# nrf52 register map
Vendor: Nordic Semiconductor; Series: nrf52; File version: 1
CPU: CM4 r0p1, little endian, MPU, FPU, 3 interrupt priority bits
Registers are 32-bit, read-write, reset 0x0 unless marked. A register's access mark holds for its fields unless they carry their own. Offsets are from the block's base; [hi:lo] are bit positions; lines under a group give offsets from that group; {n}, {i} and the like mark numbered series.

## FICR — Factory Information Configuration Registers
Base 0x10000000
0x10 CODEPAGESIZE ro reset 0xFFFFFFFF — Code memory page size
0x14 CODESIZE ro reset 0xFFFFFFFF — Code memory size
  [31:0] CODESIZE — Code memory size in number of pages
{0x60+4i} DEVICEID[{i}] (i=0..1) ro reset 0xFFFFFFFF — Description collection: Device identifier
  [31:0] DEVICEID — 64 bit unique device identifier
{0x80+4i} ER[{i}] (i=0..3) ro reset 0xFFFFFFFF — Description collection: Encryption Root, word n
  [31:0] ER — Encryption Root, word n
{0x90+4i} IR[{i}] (i=0..3) ro reset 0xFFFFFFFF — Description collection: Identity Root, word n
  [31:0] IR — Identity Root, word n
0xA0 DEVICEADDRTYPE ro reset 0xFFFFFFFF — Device address type
  [0] DEVICEADDRTYPE
    0=Public address; 1=Random address
{0xA4+4i} DEVICEADDR[{i}] (i=0..1) ro reset 0xFFFFFFFF — Description collection: Device address n
  [31:0] DEVICEADDR — 48 bit device address
0x100 INFO group — Device info
  0x00 PART ro reset 0x52832 — Part code
    [31:0] PART
      0x52832=N52832 (nRF52832); 0xFFFFFFFF=Unspecified
  0x04 VARIANT ro reset 0x41414142 — Part Variant, Hardware version and Production configuration
    [31:0] VARIANT — Part Variant, Hardware version and Production configuration, encoded as ASCII
      0x41414141=AAAA; 0x41414143=AAAC; 0x41414241=AABA; 0x41414242=AABB; 0x41414230=AAB0; 0x41424230=ABB0; 0x41414530=AAE0; 0x41424530=ABE0; 0x41414742=AAGB; 0x41424742=ABGB; 0x41414730=AAG0; 0x41424730=ABG0; 0xFFFFFFFF=Unspecified
  0x08 PACKAGE ro reset 0x2000 — Package option
    [31:0] PACKAGE
      0x2000=QF (QFxx - 48-pin QFN); 0x2001=CH (CHxx - 7x8 WLCSP 56 balls); 0x2002=CI (CIxx - 7x8 WLCSP 56 balls); 0x2005=CK (CKxx - 7x8 WLCSP 56 balls with backside coating for light protection); 0xFFFFFFFF=Unspecified
  0x0C RAM ro reset 0x40 — RAM variant
    [31:0] RAM
      16=K16 (16 kByte RAM); 32=K32 (32 kByte RAM); 64=K64 (64 kByte RAM); 0xFFFFFFFF=Unspecified
  0x10 FLASH ro reset 0x200 — Flash variant
    [31:0] FLASH
      128=K128 (128 kByte FLASH); 0x100=K256 (256 kByte FLASH); 0x200=K512 (512 kByte FLASH); 0xFFFFFFFF=Unspecified
0x404 TEMP group — Registers storing factory TEMP module linearization coefficients
  0x00 A0 ro reset 0x320 — Slope definition A0.
    [11:0] A — A (slope definition) register.
  0x04 A1 ro reset 0x343 — Slope definition A1.
    [11:0] A — A (slope definition) register.
  0x08 A2 ro reset 0x35D — Slope definition A2.
    [11:0] A — A (slope definition) register.
  0x0C A3 ro reset 0x400 — Slope definition A3.
    [11:0] A — A (slope definition) register.
  0x10 A4 ro reset 0x452 — Slope definition A4.
    [11:0] A — A (slope definition) register.
  0x14 A5 ro reset 0x37B — Slope definition A5.
    [11:0] A — A (slope definition) register.
  0x18 B0 ro reset 0x3FCC — y-intercept B0.
    [13:0] B — B (y-intercept)
  0x1C B1 ro reset 0x3F98 — y-intercept B1.
    [13:0] B — B (y-intercept)
  0x20 B2 ro reset 0x3F98 — y-intercept B2.
    [13:0] B — B (y-intercept)
  0x24 B3 ro reset 0x12 — y-intercept B3.
    [13:0] B — B (y-intercept)
  0x28 B4 ro reset 0x4D — y-intercept B4.
    [13:0] B — B (y-intercept)
  0x2C B5 ro reset 0x3E10 — y-intercept B5.
    [13:0] B — B (y-intercept)
  0x30 T0 ro reset 0xE2 — Segment end T0.
    [7:0] T — T (segment end)register.
  0x34 T1 ro — Segment end T1.
    [7:0] T — T (segment end)register.
  0x38 T2 ro reset 0x14 — Segment end T2.
    [7:0] T — T (segment end)register.
  0x3C T3 ro reset 0x19 — Segment end T3.
    [7:0] T — T (segment end)register.
  0x40 T4 ro reset 0x50 — Segment end T4.
    [7:0] T — T (segment end)register.
0x450 NFC group — Unspecified
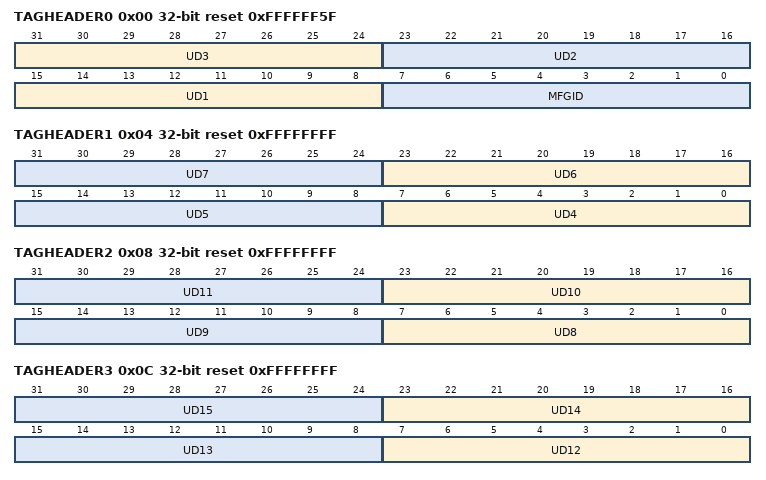
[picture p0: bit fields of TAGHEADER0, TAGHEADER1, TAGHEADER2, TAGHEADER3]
  0x00 TAGHEADER0 ro reset 0xFFFFFF5F — Default header for NFC Tag. Software can read these values to populate NFCID1_3RD_LAST, NFCID1_2ND_LAST and NFCID1_LAST.
    [31:24] UD3 — Unique identifier byte 3
    [23:16] UD2 — Unique identifier byte 2
    [15:8] UD1 — Unique identifier byte 1
    [7:0] MFGID — Default Manufacturer ID: Nordic Semiconductor ASA has ICM 0x5F
  0x04 TAGHEADER1 ro reset 0xFFFFFFFF — Default header for NFC Tag. Software can read these values to populate NFCID1_3RD_LAST, NFCID1_2ND_LAST and NFCID1_LAST.
    [8n-25:8n-32] UD{n} (n=4..7) — Unique identifier byte {n}
  0x08 TAGHEADER2 ro reset 0xFFFFFFFF — Default header for NFC Tag. Software can read these values to populate NFCID1_3RD_LAST, NFCID1_2ND_LAST and NFCID1_LAST.
    [8n-57:8n-64] UD{n} (n=8..11) — Unique identifier byte {n}
  0x0C TAGHEADER3 ro reset 0xFFFFFFFF — Default header for NFC Tag. Software can read these values to populate NFCID1_3RD_LAST, NFCID1_2ND_LAST and NFCID1_LAST.
    [8n-89:8n-96] UD{n} (n=12..15) — Unique identifier byte {n}

## Notices in the file
Copyright (c) 2010 - 2025, Nordic Semiconductor ASA All rights reserved.
SPDX-License-Identifier: BSD-3-Clause
Redistribution and use in source and binary forms, with or without
modification, are permitted provided that the following conditions are met:
1. Redistributions of source code must retain the above copyright notice, this
list of conditions and the following disclaimer.
2. Redistributions in binary form must reproduce the above copyright
notice, this list of conditions and the following disclaimer in the
documentation and/or other materials provided with the distribution.
3. Neither the name of Nordic Semiconductor ASA nor the names of its
contributors may be used to endorse or promote products derived from this
software without specific prior written permission.
THIS SOFTWARE IS PROVIDED BY THE COPYRIGHT HOLDERS AND CONTRIBUTORS "AS IS"
AND ANY EXPRESS OR IMPLIED WARRANTIES, INCLUDING, BUT NOT LIMITED TO, THE
IMPLIED WARRANTIES OF MERCHANTABILITY, AND FITNESS FOR A PARTICULAR PURPOSE
ARE DISCLAIMED. IN NO EVENT SHALL NORDIC SEMICONDUCTOR ASA OR CONTRIBUTORS BE
LIABLE FOR ANY DIRECT, INDIRECT, INCIDENTAL, SPECIAL, EXEMPLARY, OR
CONSEQUENTIAL DAMAGES (INCLUDING, BUT NOT LIMITED TO, PROCUREMENT OF
SUBSTITUTE GOODS OR SERVICES; LOSS OF USE, DATA, OR PROFITS; OR BUSINESS
INTERRUPTION) HOWEVER CAUSED AND ON ANY THEORY OF LIABILITY, WHETHER IN
CONTRACT, STRICT LIABILITY, OR TORT (INCLUDING NEGLIGENCE OR OTHERWISE)
ARISING IN ANY WAY OUT OF THE USE OF THIS SOFTWARE, EVEN IF ADVISED OF THE
POSSIBILITY OF SUCH DAMAGE.
